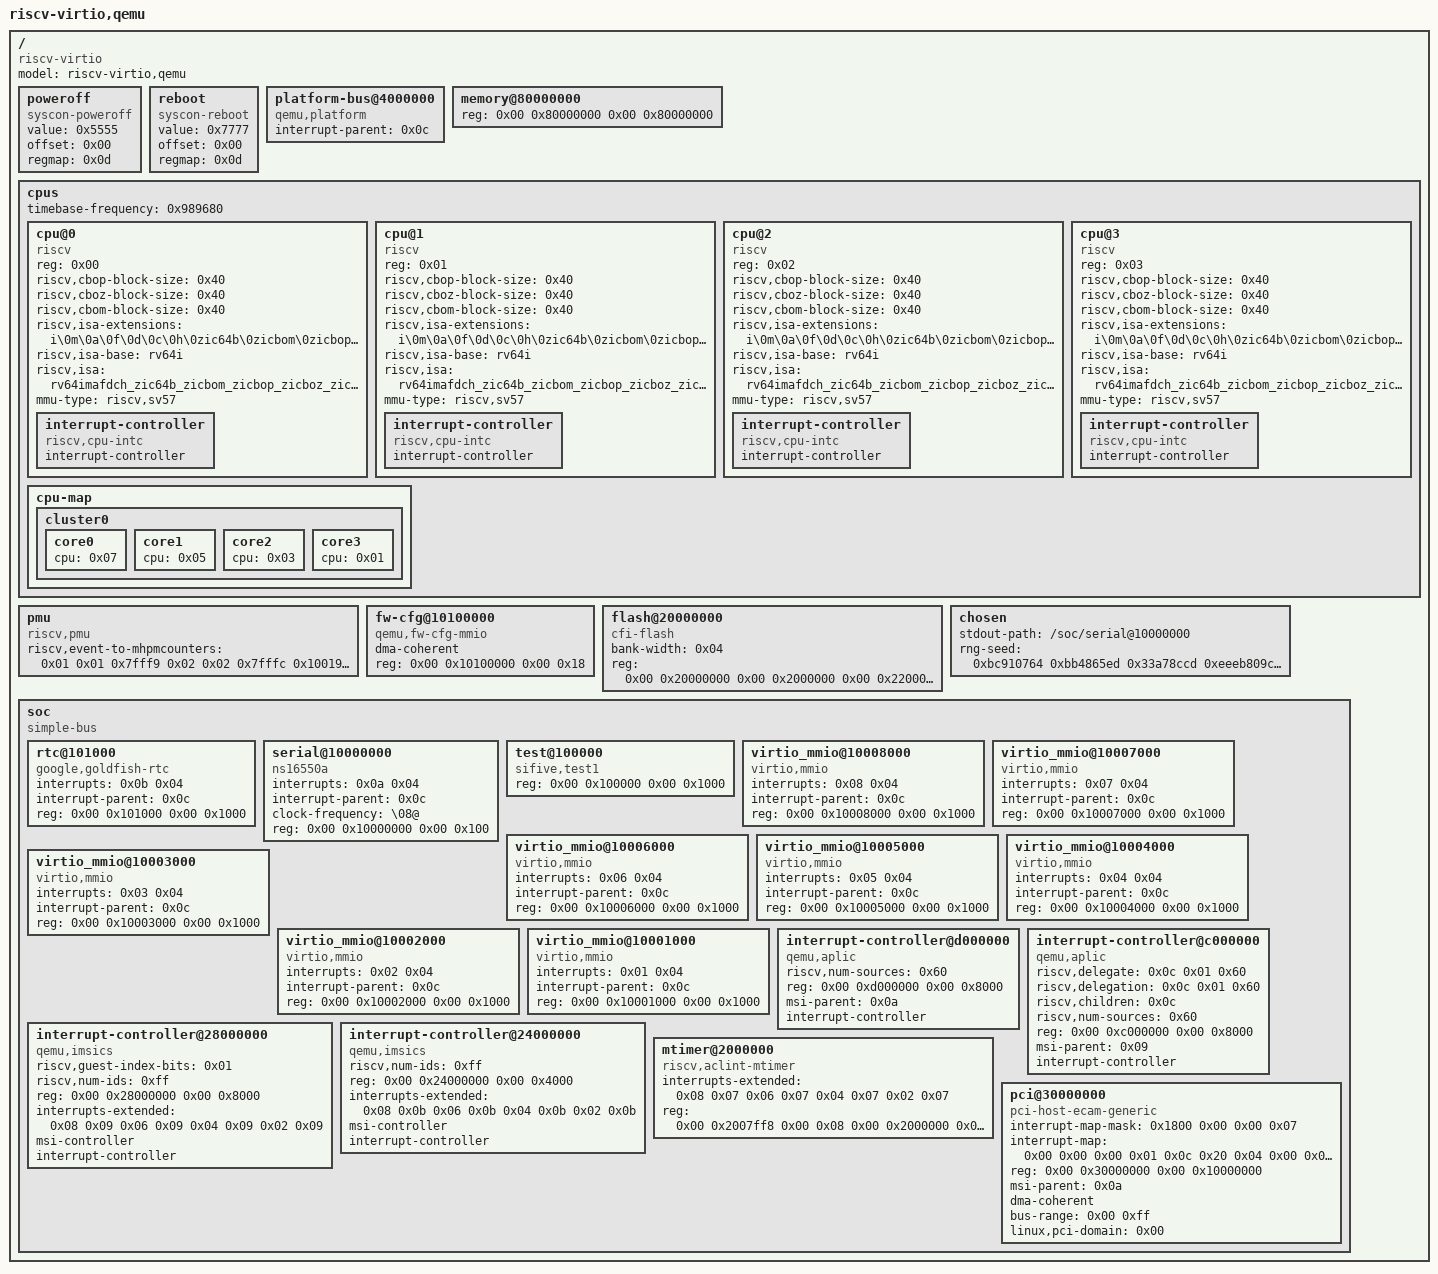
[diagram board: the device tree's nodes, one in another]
/dts-v1/;

/ {
	#address-cells = <0x02>;
	#size-cells = <0x02>;
	compatible = "riscv-virtio";
	model = "riscv-virtio,qemu";

	poweroff {
		value = <0x5555>;
		offset = <0x00>;
		regmap = <0x0d>;
		compatible = "syscon-poweroff";
	};

	reboot {
		value = <0x7777>;
		offset = <0x00>;
		regmap = <0x0d>;
		compatible = "syscon-reboot";
	};

	platform-bus@4000000 {
		interrupt-parent = <0x0c>;
		ranges = <0x00 0x00 0x4000000 0x2000000>;
		#address-cells = <0x01>;
		#size-cells = <0x01>;
		compatible = "qemu,platform\0simple-bus";
	};

	memory@80000000 {
		device_type = "memory";
		reg = <0x00 0x80000000 0x00 0x80000000>;
	};

	cpus {
		#address-cells = <0x01>;
		#size-cells = <0x00>;
		timebase-frequency = <0x989680>;

		cpu@0 {
			phandle = <0x07>;
			device_type = "cpu";
			reg = <0x00>;
			status = "okay";
			compatible = "riscv";
			riscv,cbop-block-size = <0x40>;
			riscv,cboz-block-size = <0x40>;
			riscv,cbom-block-size = <0x40>;
			riscv,isa-extensions = "i\0m\0a\0f\0d\0c\0h\0zic64b\0zicbom\0zicbop\0zicboz\0ziccamoa\0ziccif\0zicclsm\0ziccrse\0zicntr\0zicsr\0zifencei\0zihintntl\0zihintpause\0zihpm\0zmmul\0za64rs\0zaamo\0zalrsc\0zawrs\0zfa\0zca\0zcd\0zba\0zbb\0zbc\0zbs\0smaia\0ssaia\0ssccptr\0sscounterenw\0sstc\0sstvala\0sstvecd\0svadu\0svvptc";
			riscv,isa-base = "rv64i";
			riscv,isa = "rv64imafdch_zic64b_zicbom_zicbop_zicboz_ziccamoa_ziccif_zicclsm_ziccrse_zicntr_zicsr_zifencei_zihintntl_zihintpause_zihpm_zmmul_za64rs_zaamo_zalrsc_zawrs_zfa_zca_zcd_zba_zbb_zbc_zbs_smaia_ssaia_ssccptr_sscounterenw_sstc_sstvala_sstvecd_svadu_svvptc";
			mmu-type = "riscv,sv57";

			interrupt-controller {
				#interrupt-cells = <0x01>;
				interrupt-controller;
				compatible = "riscv,cpu-intc";
				phandle = <0x08>;
			};
		};

		cpu@1 {
			phandle = <0x05>;
			device_type = "cpu";
			reg = <0x01>;
			status = "okay";
			compatible = "riscv";
			riscv,cbop-block-size = <0x40>;
			riscv,cboz-block-size = <0x40>;
			riscv,cbom-block-size = <0x40>;
			riscv,isa-extensions = "i\0m\0a\0f\0d\0c\0h\0zic64b\0zicbom\0zicbop\0zicboz\0ziccamoa\0ziccif\0zicclsm\0ziccrse\0zicntr\0zicsr\0zifencei\0zihintntl\0zihintpause\0zihpm\0zmmul\0za64rs\0zaamo\0zalrsc\0zawrs\0zfa\0zca\0zcd\0zba\0zbb\0zbc\0zbs\0smaia\0ssaia\0ssccptr\0sscounterenw\0sstc\0sstvala\0sstvecd\0svadu\0svvptc";
			riscv,isa-base = "rv64i";
			riscv,isa = "rv64imafdch_zic64b_zicbom_zicbop_zicboz_ziccamoa_ziccif_zicclsm_ziccrse_zicntr_zicsr_zifencei_zihintntl_zihintpause_zihpm_zmmul_za64rs_zaamo_zalrsc_zawrs_zfa_zca_zcd_zba_zbb_zbc_zbs_smaia_ssaia_ssccptr_sscounterenw_sstc_sstvala_sstvecd_svadu_svvptc";
			mmu-type = "riscv,sv57";

			interrupt-controller {
				#interrupt-cells = <0x01>;
				interrupt-controller;
				compatible = "riscv,cpu-intc";
				phandle = <0x06>;
			};
		};

		cpu@2 {
			phandle = <0x03>;
			device_type = "cpu";
			reg = <0x02>;
			status = "okay";
			compatible = "riscv";
			riscv,cbop-block-size = <0x40>;
			riscv,cboz-block-size = <0x40>;
			riscv,cbom-block-size = <0x40>;
			riscv,isa-extensions = "i\0m\0a\0f\0d\0c\0h\0zic64b\0zicbom\0zicbop\0zicboz\0ziccamoa\0ziccif\0zicclsm\0ziccrse\0zicntr\0zicsr\0zifencei\0zihintntl\0zihintpause\0zihpm\0zmmul\0za64rs\0zaamo\0zalrsc\0zawrs\0zfa\0zca\0zcd\0zba\0zbb\0zbc\0zbs\0smaia\0ssaia\0ssccptr\0sscounterenw\0sstc\0sstvala\0sstvecd\0svadu\0svvptc";
			riscv,isa-base = "rv64i";
			riscv,isa = "rv64imafdch_zic64b_zicbom_zicbop_zicboz_ziccamoa_ziccif_zicclsm_ziccrse_zicntr_zicsr_zifencei_zihintntl_zihintpause_zihpm_zmmul_za64rs_zaamo_zalrsc_zawrs_zfa_zca_zcd_zba_zbb_zbc_zbs_smaia_ssaia_ssccptr_sscounterenw_sstc_sstvala_sstvecd_svadu_svvptc";
			mmu-type = "riscv,sv57";

			interrupt-controller {
				#interrupt-cells = <0x01>;
				interrupt-controller;
				compatible = "riscv,cpu-intc";
				phandle = <0x04>;
			};
		};

		cpu@3 {
			phandle = <0x01>;
			device_type = "cpu";
			reg = <0x03>;
			status = "okay";
			compatible = "riscv";
			riscv,cbop-block-size = <0x40>;
			riscv,cboz-block-size = <0x40>;
			riscv,cbom-block-size = <0x40>;
			riscv,isa-extensions = "i\0m\0a\0f\0d\0c\0h\0zic64b\0zicbom\0zicbop\0zicboz\0ziccamoa\0ziccif\0zicclsm\0ziccrse\0zicntr\0zicsr\0zifencei\0zihintntl\0zihintpause\0zihpm\0zmmul\0za64rs\0zaamo\0zalrsc\0zawrs\0zfa\0zca\0zcd\0zba\0zbb\0zbc\0zbs\0smaia\0ssaia\0ssccptr\0sscounterenw\0sstc\0sstvala\0sstvecd\0svadu\0svvptc";
			riscv,isa-base = "rv64i";
			riscv,isa = "rv64imafdch_zic64b_zicbom_zicbop_zicboz_ziccamoa_ziccif_zicclsm_ziccrse_zicntr_zicsr_zifencei_zihintntl_zihintpause_zihpm_zmmul_za64rs_zaamo_zalrsc_zawrs_zfa_zca_zcd_zba_zbb_zbc_zbs_smaia_ssaia_ssccptr_sscounterenw_sstc_sstvala_sstvecd_svadu_svvptc";
			mmu-type = "riscv,sv57";

			interrupt-controller {
				#interrupt-cells = <0x01>;
				interrupt-controller;
				compatible = "riscv,cpu-intc";
				phandle = <0x02>;
			};
		};

		cpu-map {

			cluster0 {

				core0 {
					cpu = <0x07>;
				};

				core1 {
					cpu = <0x05>;
				};

				core2 {
					cpu = <0x03>;
				};

				core3 {
					cpu = <0x01>;
				};
			};
		};
	};

	pmu {
		riscv,event-to-mhpmcounters = <0x01 0x01 0x7fff9 0x02 0x02 0x7fffc 0x10019 0x10019 0x7fff8 0x1001b 0x1001b 0x7fff8 0x10021 0x10021 0x7fff8>;
		compatible = "riscv,pmu";
	};

	fw-cfg@10100000 {
		dma-coherent;
		reg = <0x00 0x10100000 0x00 0x18>;
		compatible = "qemu,fw-cfg-mmio";
	};

	flash@20000000 {
		bank-width = <0x04>;
		reg = <0x00 0x20000000 0x00 0x2000000 0x00 0x22000000 0x00 0x2000000>;
		compatible = "cfi-flash";
	};

	chosen {
		stdout-path = "/soc/serial@10000000";
		rng-seed = <0xbc910764 0xbb4865ed 0x33a78ccd 0xeeeb809c 0xf3a8c22c 0xb1993bfb 0xcae1b78a 0x709d4b21>;
	};

	soc {
		#address-cells = <0x02>;
		#size-cells = <0x02>;
		compatible = "simple-bus";
		ranges;

		rtc@101000 {
			interrupts = <0x0b 0x04>;
			interrupt-parent = <0x0c>;
			reg = <0x00 0x101000 0x00 0x1000>;
			compatible = "google,goldfish-rtc";
		};

		serial@10000000 {
			interrupts = <0x0a 0x04>;
			interrupt-parent = <0x0c>;
			clock-frequency = "\08@";
			reg = <0x00 0x10000000 0x00 0x100>;
			compatible = "ns16550a";
		};

		test@100000 {
			phandle = <0x0d>;
			reg = <0x00 0x100000 0x00 0x1000>;
			compatible = "sifive,test1\0sifive,test0\0syscon";
		};

		virtio_mmio@10008000 {
			interrupts = <0x08 0x04>;
			interrupt-parent = <0x0c>;
			reg = <0x00 0x10008000 0x00 0x1000>;
			compatible = "virtio,mmio";
		};

		virtio_mmio@10007000 {
			interrupts = <0x07 0x04>;
			interrupt-parent = <0x0c>;
			reg = <0x00 0x10007000 0x00 0x1000>;
			compatible = "virtio,mmio";
		};

		virtio_mmio@10006000 {
			interrupts = <0x06 0x04>;
			interrupt-parent = <0x0c>;
			reg = <0x00 0x10006000 0x00 0x1000>;
			compatible = "virtio,mmio";
		};

		virtio_mmio@10005000 {
			interrupts = <0x05 0x04>;
			interrupt-parent = <0x0c>;
			reg = <0x00 0x10005000 0x00 0x1000>;
			compatible = "virtio,mmio";
		};

		virtio_mmio@10004000 {
			interrupts = <0x04 0x04>;
			interrupt-parent = <0x0c>;
			reg = <0x00 0x10004000 0x00 0x1000>;
			compatible = "virtio,mmio";
		};

		virtio_mmio@10003000 {
			interrupts = <0x03 0x04>;
			interrupt-parent = <0x0c>;
			reg = <0x00 0x10003000 0x00 0x1000>;
			compatible = "virtio,mmio";
		};

		virtio_mmio@10002000 {
			interrupts = <0x02 0x04>;
			interrupt-parent = <0x0c>;
			reg = <0x00 0x10002000 0x00 0x1000>;
			compatible = "virtio,mmio";
		};

		virtio_mmio@10001000 {
			interrupts = <0x01 0x04>;
			interrupt-parent = <0x0c>;
			reg = <0x00 0x10001000 0x00 0x1000>;
			compatible = "virtio,mmio";
		};

		interrupt-controller@d000000 {
			phandle = <0x0c>;
			riscv,num-sources = <0x60>;
			reg = <0x00 0xd000000 0x00 0x8000>;
			msi-parent = <0x0a>;
			interrupt-controller;
			#interrupt-cells = <0x02>;
			#address-cells = <0x00>;
			compatible = "qemu,aplic\0riscv,aplic";
		};

		interrupt-controller@c000000 {
			phandle = <0x0b>;
			riscv,delegate = <0x0c 0x01 0x60>;
			riscv,delegation = <0x0c 0x01 0x60>;
			riscv,children = <0x0c>;
			riscv,num-sources = <0x60>;
			reg = <0x00 0xc000000 0x00 0x8000>;
			msi-parent = <0x09>;
			interrupt-controller;
			#interrupt-cells = <0x02>;
			#address-cells = <0x00>;
			compatible = "qemu,aplic\0riscv,aplic";
		};

		interrupt-controller@28000000 {
			phandle = <0x0a>;
			riscv,guest-index-bits = <0x01>;
			riscv,num-ids = <0xff>;
			reg = <0x00 0x28000000 0x00 0x8000>;
			interrupts-extended = <0x08 0x09 0x06 0x09 0x04 0x09 0x02 0x09>;
			msi-controller;
			interrupt-controller;
			#interrupt-cells = <0x00>;
			compatible = "qemu,imsics\0riscv,imsics";
		};

		interrupt-controller@24000000 {
			phandle = <0x09>;
			riscv,num-ids = <0xff>;
			reg = <0x00 0x24000000 0x00 0x4000>;
			interrupts-extended = <0x08 0x0b 0x06 0x0b 0x04 0x0b 0x02 0x0b>;
			msi-controller;
			interrupt-controller;
			#interrupt-cells = <0x00>;
			compatible = "qemu,imsics\0riscv,imsics";
		};

		mtimer@2000000 {
			interrupts-extended = <0x08 0x07 0x06 0x07 0x04 0x07 0x02 0x07>;
			reg = <0x00 0x2007ff8 0x00 0x08 0x00 0x2000000 0x00 0x7ff8>;
			compatible = "riscv,aclint-mtimer";
		};

		pci@30000000 {
			interrupt-map-mask = <0x1800 0x00 0x00 0x07>;
			interrupt-map = <0x00 0x00 0x00 0x01 0x0c 0x20 0x04 0x00 0x00 0x00 0x02 0x0c 0x21 0x04 0x00 0x00 0x00 0x03 0x0c 0x22 0x04 0x00 0x00 0x00 0x04 0x0c 0x23 0x04 0x800 0x00 0x00 0x01 0x0c 0x21 0x04 0x800 0x00 0x00 0x02 0x0c 0x22 0x04 0x800 0x00 0x00 0x03 0x0c 0x23 0x04 0x800 0x00 0x00 0x04 0x0c 0x20 0x04 0x1000 0x00 0x00 0x01 0x0c 0x22 0x04 0x1000 0x00 0x00 0x02 0x0c 0x23 0x04 0x1000 0x00 0x00 0x03 0x0c 0x20 0x04 0x1000 0x00 0x00 0x04 0x0c 0x21 0x04 0x1800 0x00 0x00 0x01 0x0c 0x23 0x04 0x1800 0x00 0x00 0x02 0x0c 0x20 0x04 0x1800 0x00 0x00 0x03 0x0c 0x21 0x04 0x1800 0x00 0x00 0x04 0x0c 0x22 0x04>;
			ranges = <0x1000000 0x00 0x00 0x00 0x3000000 0x00 0x10000 0x2000000 0x00 0x40000000 0x00 0x40000000 0x00 0x40000000 0x3000000 0x04 0x00 0x04 0x00 0x04 0x00>;
			reg = <0x00 0x30000000 0x00 0x10000000>;
			msi-parent = <0x0a>;
			dma-coherent;
			bus-range = <0x00 0xff>;
			linux,pci-domain = <0x00>;
			device_type = "pci";
			compatible = "pci-host-ecam-generic";
			#size-cells = <0x02>;
			#interrupt-cells = <0x01>;
			#address-cells = <0x03>;
		};
	};
};
